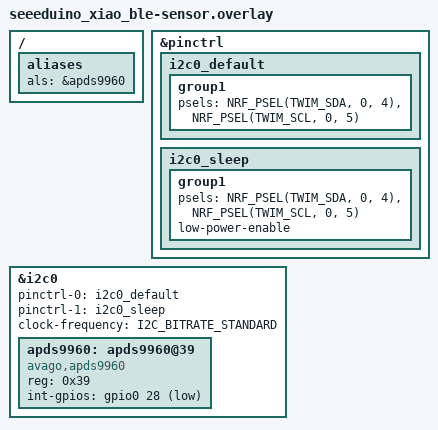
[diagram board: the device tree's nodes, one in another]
/*
 * APDS9960 Ambient Light Sensor Overlay for Prospector Scanner
 * 
 * This overlay file enables I2C and APDS9960 sensor support.
 * Only include this when you have the sensor hardware connected.
 * 
 * Usage:
 * 1. Set CONFIG_PROSPECTOR_USE_AMBIENT_LIGHT_SENSOR=y in your .conf
 * 2. Build with west build - this overlay is automatically included
 *    when the sensor config is enabled
 * 
 * Hardware connections:
 * - SDA: D4 (P0.04)
 * - SCL: D5 (P0.05) 
 * - VCC: 3.3V
 * - GND: GND
 */

/ {
    // Enable ambient light sensor alias
    aliases {
        als = &apds9960;
    };
};

// I2C pinctrl configuration for sensor support
&pinctrl {
    i2c0_default: i2c0_default {
        group1 {
            psels = <NRF_PSEL(TWIM_SDA, 0, 4)>,  // Pin 4 (D4) = P0.04 = SDA
                    <NRF_PSEL(TWIM_SCL, 0, 5)>;  // Pin 5 (D5) = P0.05 = SCL
        };
    };

    i2c0_sleep: i2c0_sleep {
        group1 {
            psels = <NRF_PSEL(TWIM_SDA, 0, 4)>,  // Pin 4 (D4) = P0.04 = SDA
                    <NRF_PSEL(TWIM_SCL, 0, 5)>;  // Pin 5 (D5) = P0.05 = SCL
            low-power-enable;
        };
    };
};

// Conditionally enable I2C based on user configuration
&i2c0 {
    // Only enable I2C when sensor support is explicitly requested
    status = IS_ENABLED(CONFIG_PROSPECTOR_USE_AMBIENT_LIGHT_SENSOR) ? "okay" : "disabled";
    pinctrl-0 = <&i2c0_default>;
    pinctrl-1 = <&i2c0_sleep>;
    pinctrl-names = "default", "sleep";
    clock-frequency = <I2C_BITRATE_STANDARD>; // 100kHz - most compatible speed
    
    // APDS9960 ambient light sensor
    apds9960: apds9960@39 {
        compatible = "avago,apds9960";
        // Only enable sensor when support is requested
        status = IS_ENABLED(CONFIG_PROSPECTOR_USE_AMBIENT_LIGHT_SENSOR) ? "okay" : "disabled";
        reg = <0x39>;
        int-gpios = <&gpio0 28 (GPIO_PULL_UP | GPIO_ACTIVE_LOW)>; // Optional interrupt on D2
    };
};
